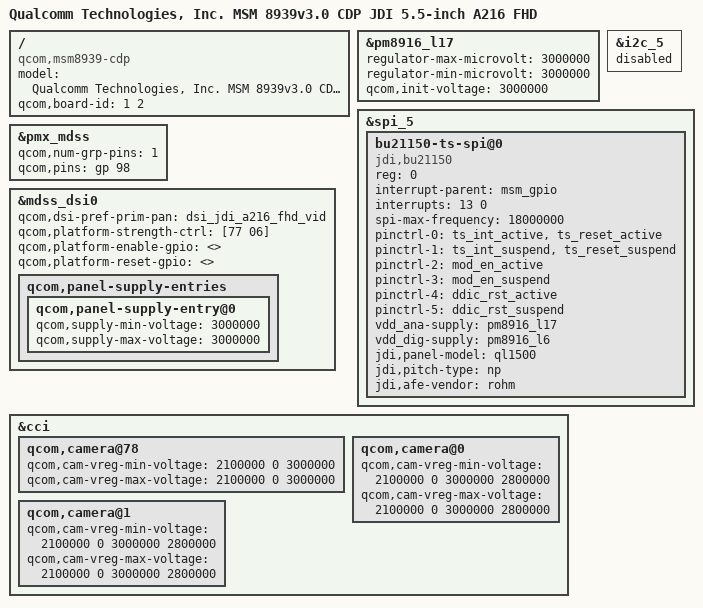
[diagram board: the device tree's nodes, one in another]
/*
 * Copyright (c) 2015, The Linux Foundation. All rights reserved.
 *
 * This program is free software; you can redistribute it and/or modify
 * it under the terms of the GNU General Public License version 2 and
 * only version 2 as published by the Free Software Foundation.
 *
 * This program is distributed in the hope that it will be useful,
 * but WITHOUT ANY WARRANTY; without even the implied warranty of
 * MERCHANTABILITY or FITNESS FOR A PARTICULAR PURPOSE.  See the
 * GNU General Public License for more details.
 */

/dts-v1/;

#include "msm8939-v3.0.dtsi"
#include "msm8939-cdp.dtsi"
#include "msm8939-regulator.dtsi"

/ {
	model = "Qualcomm Technologies, Inc. MSM 8939v3.0 CDP JDI 5.5-inch A216 FHD";
	compatible = "qcom,msm8939-cdp", "qcom,msm8939", "qcom,cdp";
	qcom,board-id = <1 2>;
};

&pm8916_l17 {
	regulator-max-microvolt = <3000000>;
	regulator-min-microvolt = <3000000>;
	qcom,init-voltage = <3000000>;
};

&i2c_5 {  /* BLSP1 QUP5 */
	status = "disabled";
};

&spi_5 {
	status = "okay";
	bu21150-ts-spi@0 {
		compatible = "jdi,bu21150";
		reg = <0>;
		interrupt-parent = <&msm_gpio>;
		interrupts = <13 0>;
		spi-max-frequency = <18000000>;
		pinctrl-names = "pmx_ts_active","pmx_ts_suspend",
				"mod_en_active", "mod_en_suspend",
				"ddic_rst_active", "ddic_rst_suspend";
		pinctrl-0 = <&ts_int_active &ts_reset_active>;
		pinctrl-1 = <&ts_int_suspend &ts_reset_suspend>;
		pinctrl-2 = <&mod_en_active>;
		pinctrl-3 = <&mod_en_suspend>;
		pinctrl-4 = <&ddic_rst_active>;
		pinctrl-5 = <&ddic_rst_suspend>;
		vdd_ana-supply = <&pm8916_l17>;
		vdd_dig-supply = <&pm8916_l6>;
		jdi,panel-model = "ql1500";
		jdi,pitch-type = "np";
		jdi,afe-vendor = "rohm";
	};
};

&pmx_mdss {
	qcom,num-grp-pins = <1>;
	qcom,pins = <&gp 98>;
};

&mdss_dsi0 {
	qcom,dsi-pref-prim-pan = <&dsi_jdi_a216_fhd_vid>;
	qcom,platform-strength-ctrl = [77 06];
	qcom,platform-enable-gpio = <>;
	qcom,platform-reset-gpio = <>;

	qcom,panel-supply-entries {
		qcom,panel-supply-entry@0 {
			qcom,supply-min-voltage = <3000000>;
			qcom,supply-max-voltage = <3000000>;
		};
	};
};

#include "msm8939-camera-sensor-cdp.dtsi"

&cci {
	qcom,camera@78 {
		qcom,cam-vreg-min-voltage = <2100000 0 3000000>;
		qcom,cam-vreg-max-voltage = <2100000 0 3000000>;
	};

	qcom,camera@0 {
		qcom,cam-vreg-min-voltage = <2100000 0 3000000 2800000>;
		qcom,cam-vreg-max-voltage = <2100000 0 3000000 2800000>;
	};

	qcom,camera@1 {
		qcom,cam-vreg-min-voltage = <2100000 0 3000000 2800000>;
		qcom,cam-vreg-max-voltage = <2100000 0 3000000 2800000>;
	};
};
